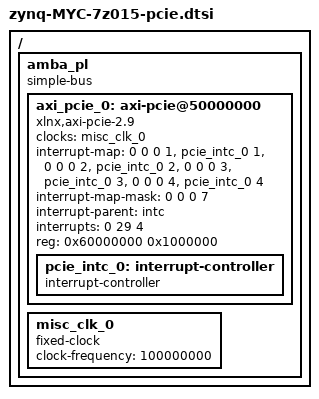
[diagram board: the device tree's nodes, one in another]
/*
 * CAUTION: This file is automatically generated by Xilinx.
 * Version:  
 * Today is: Thu Aug  1 08:47:29 2019
 */


/ {
	amba_pl: amba_pl {
		#address-cells = <1>;
		#size-cells = <1>;
		compatible = "simple-bus";
		ranges ;
        axi_pcie_0: axi-pcie@50000000 {
			#address-cells = <3>;
			#interrupt-cells = <1>;
			#size-cells = <2>;
			clock-names = "REFCLK";
			clocks = <&misc_clk_0>;
			compatible = "xlnx,axi-pcie-2.9", "xlnx,axi-pcie-host-1.00.a";
			device_type = "pci";
			interrupt-map = <0 0 0 1 &pcie_intc_0 1>, <0 0 0 2 &pcie_intc_0 2>, <0 0 0 3 &pcie_intc_0 3>, <0 0 0 4 &pcie_intc_0 4>;
			interrupt-map-mask = <0 0 0 7>;
			interrupt-names = "interrupt_out";
			interrupt-parent = <&intc>;
			interrupts = <0 29 4>;
			ranges = <0x02000000 0x00000000 0x60000000 0x50000000 0x00000000 0x01000000>;
			reg = <0x60000000 0x1000000>;
			pcie_intc_0: interrupt-controller {
				#address-cells = <0>;
				#interrupt-cells = <1>;
				interrupt-controller ;
			};
		};
		misc_clk_0: misc_clk_0 {
			#clock-cells = <0>;
			clock-frequency = <100000000>;
			compatible = "fixed-clock";
		};
	};
};
